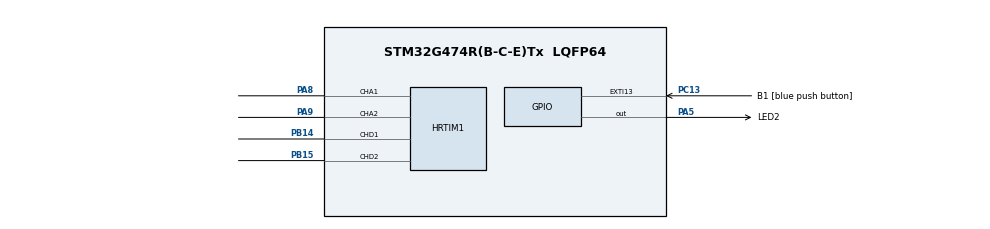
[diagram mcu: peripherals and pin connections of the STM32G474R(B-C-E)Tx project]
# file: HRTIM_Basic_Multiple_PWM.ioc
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HRTIM1.ADCTrigger_Id1=__NULL
HRTIM1.ADCTrigger_Id10=__NULL
HRTIM1.ADCTrigger_Id2=__NULL
HRTIM1.ADCTrigger_Id3=__NULL
HRTIM1.ADCTrigger_Id4=__NULL
HRTIM1.ADCTrigger_Id5=__NULL
HRTIM1.ADCTrigger_Id6=__NULL
HRTIM1.ADCTrigger_Id7=__NULL
HRTIM1.ADCTrigger_Id8=__NULL
HRTIM1.ADCTrigger_Id9=__NULL
HRTIM1.AutoDelayedMode2-Output_TA1TA2=HRTIM_AUTODELAYEDMODE_REGULAR
HRTIM1.AutoDelayedMode2-Output_TD1TD2=HRTIM_AUTODELAYEDMODE_REGULAR
HRTIM1.BurstDMAconfig-Output_TA1TA2=__NULL
HRTIM1.BurstDMAconfig-Output_TD1TD2=__NULL
HRTIM1.BurstMode-Output_TA1TA2=HRTIM_TIMERBURSTMODE_MAINTAINCLOCK
HRTIM1.BurstMode-Output_TD1TD2=HRTIM_TIMERBURSTMODE_MAINTAINCLOCK
HRTIM1.BurstModeEntryDelayed1-Output_TA1TA2=HRTIM_OUTPUTBURSTMODEENTRY_REGULAR
HRTIM1.BurstModeEntryDelayed1-Output_TD1TD2=HRTIM_OUTPUTBURSTMODEENTRY_REGULAR
HRTIM1.BurstModeEntryDelayed2-Output_TA1TA2=HRTIM_OUTPUTBURSTMODEENTRY_REGULAR
HRTIM1.BurstModeEntryDelayed2-Output_TD1TD2=HRTIM_OUTPUTBURSTMODEENTRY_REGULAR
HRTIM1.CaptureUnit1-Output_TA1TA2=__NULL
HRTIM1.CaptureUnit1-Output_TD1TD2=__NULL
HRTIM1.CaptureUnit2-Output_TA1TA2=__NULL
HRTIM1.CaptureUnit2-Output_TD1TD2=__NULL
HRTIM1.ChopperModeEnable1-Output_TA1TA2=HRTIM_OUTPUTCHOPPERMODE_DISABLED
HRTIM1.ChopperModeEnable1-Output_TD1TD2=HRTIM_OUTPUTCHOPPERMODE_DISABLED
HRTIM1.ChopperModeEnable2-Output_TA1TA2=HRTIM_OUTPUTCHOPPERMODE_DISABLED
HRTIM1.ChopperModeEnable2-Output_TD1TD2=HRTIM_OUTPUTCHOPPERMODE_DISABLED
HRTIM1.ChopperModeconfig-Output_TA1TA2=__NULL
HRTIM1.ChopperModeconfig-Output_TD1TD2=__NULL
HRTIM1.CompareUnit1-Output_TA1TA2=HRTIM_COMPAREUNIT_1
HRTIM1.CompareUnit1-Output_TD1TD2=HRTIM_COMPAREUNIT_1
HRTIM1.CompareUnit2-Output_TA1TA2=HRTIM_COMPAREUNIT_2
HRTIM1.CompareUnit2-Output_TD1TD2=HRTIM_COMPAREUNIT_2
HRTIM1.CompareUnit3-Output_TA1TA2=HRTIM_COMPAREUNIT_3
HRTIM1.CompareUnit3-Output_TD1TD2=__NULL
HRTIM1.CompareUnit4-Output_TA1TA2=__NULL
HRTIM1.CompareUnit4-Output_TD1TD2=__NULL
HRTIM1.CompareValue1-Output_TA1TA2=TIMA_PERIOD/4
HRTIM1.CompareValue1-Output_TD1TD2=TIMD_PERIOD/4
HRTIM1.CompareValue2-Output_TA1TA2=TIMA_PERIOD/2
HRTIM1.CompareValue2-Output_TD1TD2=(3*TIMD_PERIOD)/4
HRTIM1.CompareValue3-Output_TA1TA2=(3*TIMA_PERIOD)/4
HRTIM1.Configuration_TA=Waveform
HRTIM1.Configuration_TD=Waveform
HRTIM1.DACSynchro-Output_TA1TA2=HRTIM_DACSYNC_NONE
HRTIM1.DACSynchro-Output_TD1TD2=HRTIM_DACSYNC_NONE
HRTIM1.DeadTimeInsertion-Output_TA1TA2=HRTIM_TIMDEADTIMEINSERTION_DISABLED
HRTIM1.DeadTimeInsertion-Output_TD1TD2=HRTIM_TIMDEADTIMEINSERTION_DISABLED
HRTIM1.Deadtimeconfig-Output_TA1TA2=__NULL
HRTIM1.Deadtimeconfig-Output_TD1TD2=__NULL
HRTIM1.DelayedProtectionMode-Output_TA1TA2=HRTIM_TIMER_A_B_C_DELAYEDPROTECTION_DISABLED
HRTIM1.DelayedProtectionMode-Output_TD1TD2=HRTIM_TIMER_D_E_DELAYEDPROTECTION_DISABLED
HRTIM1.DualChannelDacEnableFake_TA-Output_TA1TA2=HRTIM_TIMER_DCDE_DISABLED
HRTIM1.DualChannelDacEnableFake_TD-Output_TD1TD2=HRTIM_TIMER_DCDE_DISABLED
HRTIM1.Enable=HRTIM_BURSTMODECTL_DISABLED
HRTIM1.Event1-Output_TA1TA2=__NULL
HRTIM1.Event1-Output_TD1TD2=__NULL
HRTIM1.Event10-Output_TA1TA2=__NULL
HRTIM1.Event10-Output_TD1TD2=__NULL
HRTIM1.Event2-Output_TA1TA2=__NULL
HRTIM1.Event2-Output_TD1TD2=__NULL
HRTIM1.Event3-Output_TA1TA2=__NULL
HRTIM1.Event3-Output_TD1TD2=__NULL
HRTIM1.Event4-Output_TA1TA2=__NULL
HRTIM1.Event4-Output_TD1TD2=__NULL
HRTIM1.Event5-Output_TA1TA2=__NULL
HRTIM1.Event5-Output_TD1TD2=__NULL
HRTIM1.Event6-Output_TA1TA2=__NULL
HRTIM1.Event6-Output_TD1TD2=__NULL
HRTIM1.Event7-Output_TA1TA2=__NULL
HRTIM1.Event7-Output_TD1TD2=__NULL
HRTIM1.Event8-Output_TA1TA2=__NULL
HRTIM1.Event8-Output_TD1TD2=__NULL
HRTIM1.Event9-Output_TA1TA2=__NULL
HRTIM1.Event9-Output_TD1TD2=__NULL
HRTIM1.EventEnableA-Output_TA1TA2=__NULL
HRTIM1.EventEnableA-Output_TD1TD2=__NULL
HRTIM1.Event_EEV1=__NULL
HRTIM1.Event_EEV10=__NULL
HRTIM1.Event_EEV2=__NULL
HRTIM1.Event_EEV3=__NULL
HRTIM1.Event_EEV4=__NULL
HRTIM1.Event_EEV5=__NULL
HRTIM1.Event_EEV6=__NULL
HRTIM1.Event_EEV7=__NULL
HRTIM1.Event_EEV8=__NULL
HRTIM1.Event_EEV9=__NULL
HRTIM1.FaultLevel1-Output_TA1TA2=HRTIM_OUTPUTFAULTLEVEL_NONE
HRTIM1.FaultLevel1-Output_TD1TD2=HRTIM_OUTPUTFAULTLEVEL_NONE
HRTIM1.FaultLevel2-Output_TA1TA2=HRTIM_OUTPUTFAULTLEVEL_NONE
HRTIM1.FaultLevel2-Output_TD1TD2=HRTIM_OUTPUTFAULTLEVEL_NONE
HRTIM1.FaultLock-Output_TA1TA2=HRTIM_TIMFAULTLOCK_READWRITE
HRTIM1.FaultLock-Output_TD1TD2=HRTIM_TIMFAULTLOCK_READWRITE
HRTIM1.Fault_Line1=__NULL
HRTIM1.Fault_Line2=__NULL
HRTIM1.Fault_Line3=__NULL
HRTIM1.Fault_Line4=__NULL
HRTIM1.Fault_Line5=__NULL
HRTIM1.Fault_Line6=__NULL
HRTIM1.GreaterCMP1_TA=HRTIM_TIMERGTCMP1_GREATER
HRTIM1.GreaterCMP1_TD=HRTIM_TIMERGTCMP1_EQUAL
HRTIM1.GreaterCMP3_TA=HRTIM_TIMERGTCMP3_EQUAL
HRTIM1.HRTIMInterruptResquests1=HRTIM_IT_NONE
HRTIM1.HRTIMInterruptResquests2=HRTIM_IT_NONE
HRTIM1.HRTIMInterruptResquests3=HRTIM_IT_NONE
HRTIM1.HRTIMInterruptResquests4=HRTIM_IT_NONE
HRTIM1.HRTIMInterruptResquests5=HRTIM_IT_NONE
HRTIM1.HRTIMInterruptResquests6=HRTIM_IT_NONE
HRTIM1.HRTIMInterruptResquests7=HRTIM_IT_NONE
HRTIM1.HRTIMInterruptResquests8=HRTIM_IT_NONE
HRTIM1.HRTIMInterruptResquests9=HRTIM_IT_NONE
HRTIM1.IdleLevel1-Output_TA1TA2=HRTIM_OUTPUTIDLELEVEL_INACTIVE
HRTIM1.IdleLevel1-Output_TD1TD2=HRTIM_OUTPUTIDLELEVEL_INACTIVE
HRTIM1.IdleLevel2-Output_TA1TA2=HRTIM_OUTPUTIDLELEVEL_INACTIVE
HRTIM1.IdleLevel2-Output_TD1TD2=HRTIM_OUTPUTIDLELEVEL_INACTIVE
HRTIM1.IdleMode1-Output_TA1TA2=HRTIM_OUTPUTIDLEMODE_NONE
HRTIM1.IdleMode1-Output_TD1TD2=HRTIM_OUTPUTIDLEMODE_NONE
HRTIM1.IdleMode2-Output_TA1TA2=HRTIM_OUTPUTIDLEMODE_NONE
HRTIM1.IdleMode2-Output_TD1TD2=HRTIM_OUTPUTIDLEMODE_NONE
HRTIM1.InterleavedMode-Output_TA1TA2=HRTIM_INTERLEAVED_MODE_DISABLED
HRTIM1.InterleavedMode-Output_TD1TD2=HRTIM_INTERLEAVED_MODE_DISABLED
HRTIM1.ModeTimeBase-Output_TA1TA2=HRTIM_MODE_CONTINUOUS
HRTIM1.ModeTimeBase-Output_TD1TD2=HRTIM_MODE_CONTINUOUS
HRTIM1.NumberDMARequests_TA=0
HRTIM1.NumberDMARequests_TD=0
HRTIM1.NumberFaultEnable-Output_TA1TA2=0
HRTIM1.NumberFaultEnable-Output_TD1TD2=0
HRTIM1.NumberInterruptRequests-Output_TA1TA2=0
HRTIM1.NumberInterruptRequests-Output_TD1TD2=0
HRTIM1.NumberResetSource1-Output_TA1TA2=1
HRTIM1.NumberResetSource1-Output_TD1TD2=1
HRTIM1.NumberResetSource2_TA=1
HRTIM1.NumberResetSource2_TD=1
HRTIM1.NumberResetTrigger-Output_TA1TA2=0
HRTIM1.NumberResetTrigger-Output_TD1TD2=0
HRTIM1.NumberSetSource1-Output_TA1TA2=1
HRTIM1.NumberSetSource1-Output_TD1TD2=1
HRTIM1.NumberSetSource2_TA=1
HRTIM1.NumberSetSource2_TD=1
HRTIM1.NumberUpdateTrigger-Output_TA1TA2=0
HRTIM1.NumberUpdateTrigger-Output_TD1TD2=0
HRTIM1.Output1-Output_TA1TA2=HRTIM_OUTPUT_TA1
HRTIM1.Output1-Output_TD1TD2=HRTIM_OUTPUT_TD1
HRTIM1.Output2-Output_TA1TA2=HRTIM_OUTPUT_TA2
HRTIM1.Output2-Output_TD1TD2=HRTIM_OUTPUT_TD2
HRTIM1.Periode_TA=TIMA_PERIOD
HRTIM1.Periode_TD=TIMD_PERIOD
HRTIM1.Polarity1-Output_TA1TA2=HRTIM_OUTPUTPOLARITY_HIGH
HRTIM1.Polarity1-Output_TD1TD2=HRTIM_OUTPUTPOLARITY_HIGH
HRTIM1.Polarity2-Output_TA1TA2=HRTIM_OUTPUTPOLARITY_HIGH
HRTIM1.Polarity2-Output_TD1TD2=HRTIM_OUTPUTPOLARITY_HIGH
HRTIM1.PreloadEnable-Output_TA1TA2=HRTIM_PRELOAD_DISABLED
HRTIM1.PreloadEnable-Output_TD1TD2=HRTIM_PRELOAD_DISABLED
HRTIM1.PushPull-Output_TA1TA2=HRTIM_TIMPUSHPULLMODE_DISABLED
HRTIM1.PushPull-Output_TD1TD2=HRTIM_TIMPUSHPULLMODE_DISABLED
HRTIM1.ReSyncUpdate-Output_TA1TA2=HRTIM_TIMERESYNC_UPDATE_UNCONDITIONAL
HRTIM1.ReSyncUpdate-Output_TD1TD2=HRTIM_TIMERESYNC_UPDATE_UNCONDITIONAL
HRTIM1.RepetitionUpdate-Output_TA1TA2=HRTIM_UPDATEONREPETITION_DISABLED
HRTIM1.RepetitionUpdate-Output_TD1TD2=HRTIM_UPDATEONREPETITION_DISABLED
HRTIM1.ResetOnSync-Output_TA1TA2=HRTIM_SYNCRESET_DISABLED
HRTIM1.ResetOnSync-Output_TD1TD2=HRTIM_SYNCRESET_DISABLED
HRTIM1.ResetOutput1_Source1-Output_TA1TA2=HRTIM_OUTPUTRESET_TIMCMP1
HRTIM1.ResetOutput1_Source1-Output_TD1TD2=HRTIM_OUTPUTRESET_TIMCMP1
HRTIM1.ResetOutput2_Source1-Output_TA1TA2=HRTIM_OUTPUTRESET_TIMCMP3
HRTIM1.ResetOutput2_Source1-Output_TD1TD2=HRTIM_OUTPUTRESET_TIMPER
HRTIM1.ResetUpdate-Output_TA1TA2=HRTIM_TIMUPDATEONRESET_DISABLED
HRTIM1.ResetUpdate-Output_TD1TD2=HRTIM_TIMUPDATEONRESET_DISABLED
HRTIM1.SetOutput1_Source1-Output_TA1TA2=HRTIM_OUTPUTSET_TIMPER
HRTIM1.SetOutput1_Source1-Output_TD1TD2=HRTIM_OUTPUTSET_TIMPER
HRTIM1.SetOutput2_Source1-Output_TA1TA2=HRTIM_OUTPUTSET_TIMCMP2
HRTIM1.SetOutput2_Source1-Output_TD1TD2=HRTIM_OUTPUTSET_TIMCMP2
HRTIM1.StartOnSync-Output_TA1TA2=HRTIM_SYNCSTART_DISABLED
HRTIM1.StartOnSync-Output_TD1TD2=HRTIM_SYNCSTART_DISABLED
HRTIM1.SwapA=__NULL
HRTIM1.SwapD=__NULL
HRTIM1.SyncOptions=HRTIM_SYNCOPTION_NONE
HRTIM1.TimerIdx-Output_TA1TA2=HRTIM_TIMERINDEX_TIMER_A
HRTIM1.TimerIdx-Output_TD1TD2=HRTIM_TIMERINDEX_TIMER_D
HRTIM1.TrigHalf_TA=HRTIM_TIMERTRIGHALF_DISABLED
HRTIM1.TrigHalf_TD=HRTIM_TIMERTRIGHALF_DISABLED
HRTIM1.UpDownMode-Output_TA1TA2=HRTIM_TIMERUPDOWNMODE_UP
HRTIM1.UpDownMode-Output_TD1TD2=HRTIM_TIMERUPDOWNMODE_UP
HRTIM1.UpdateGating-Output_TA1TA2=HRTIM_UPDATEGATING_INDEPENDENT
HRTIM1.UpdateGating-Output_TD1TD2=HRTIM_UPDATEGATING_INDEPENDENT
Mcu.Family=STM32G4
Mcu.Name=STM32G474R(B-C-E)Tx
Mcu.Package=LQFP64
Mcu.UserConstants=HRTIM_INPUT_CLOCK,170000000;TIMA_PWM_FREQ,100000
NVIC.EXTI15_10_IRQn=true\:0\:0\:false\:false\:true\:true\:true\:true
NVIC.PriorityGroup=NVIC_PRIORITYGROUP_4
PA13.GPIO_Label=T_SWDIO
PA13.Mode=Serial_Wire
PA13.Signal=SYS_JTMS-SWDIO
PA14.GPIO_Label=T_SWCLK
PA14.Mode=Serial_Wire
PA14.Signal=SYS_JTCK-SWCLK
PA5.GPIO_Label=LED2
PA5.Signal=GPIO_Output
PA8.Mode=Output_TA1TA2
PA8.Signal=HRTIM1_CHA1
PA9.Mode=Output_TA1TA2
PA9.Signal=HRTIM1_CHA2
PB14.Mode=Output_TD1TD2
PB14.Signal=HRTIM1_CHD1
PB15.Mode=Output_TD1TD2
PB15.Signal=HRTIM1_CHD2
PB3.GPIO_Label=T_SWO
PB3.Signal=SYS_JTDO-SWO
PC13.GPIO_Label=B1 [blue push button]
PC13.Signal=GPXTI13
PC14-OSC32_IN.Signal=RCC_OSC32_IN
PC15-OSC32_OUT.Signal=RCC_OSC32_OUT
PC4.GPIO_Label=USART1_TX [STLINKV3E_VCP_RX]
PC4.Signal=USART1_TX
PC5.GPIO_Label=USART1_RX [STLINKV3E_VCP_TX]
PC5.Signal=USART1_RX
PF0-OSC_IN.Mode=HSE-External-Oscillator
PF0-OSC_IN.Signal=RCC_OSC_IN
PF1-OSC_OUT.Mode=HSE-External-Oscillator
PF1-OSC_OUT.Signal=RCC_OSC_OUT
ProjectManager.HeapSize=0x200
ProjectManager.StackSize=0x400
ProjectManager.TargetToolchain=EWARM V8.32
RCC.ADC12Freq_Value=170000000
RCC.ADC345Freq_Value=170000000
RCC.AHBFreq_Value=170000000
RCC.APB1Freq_Value=170000000
RCC.APB1TimFreq_Value=170000000
RCC.APB2Freq_Value=170000000
RCC.APB2TimFreq_Value=170000000
RCC.CortexFreq_Value=170000000
RCC.EXTERNAL_CLOCK_VALUE=12288000
RCC.HCLKFreq_Value=170000000
RCC.HSE_VALUE=24000000
RCC.HSI48_VALUE=48000000
RCC.HSI_VALUE=16000000
RCC.LSE_VALUE=32768
RCC.PLLM=RCC_PLLM_DIV6
RCC.PLLN=85
RCC.PLLSourceVirtual=RCC_PLLSOURCE_HSE
RCC.SYSCLKFreq_VALUE=170000000
RCC.SYSCLKSource=RCC_SYSCLKSOURCE_PLLCLK
RCC.USBFreq_Value=170000000
RCC.VCOOutputFreq_Value=340000000
VP_SYS_VS_DBSignals.Mode=DisableDeadBatterySignals
board=custom

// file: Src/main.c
/* USER CODE BEGIN Header */
/**
  ******************************************************************************
  * @file    Examples_LL/HRTIM/HRTIM_Basic_Multiple_PWM/Src/main.c
  * @author  MCD Application Team
  * @brief   This example describes how to configure and use HRTIM through
  *          the STM32G4xx LL API.
  ******************************************************************************
  * @attention
  *
  * Copyright (c) 2019 STMicroelectronics.
  * All rights reserved.
  *
  * This software is licensed under terms that can be found in the LICENSE file
  * in the root directory of this software component.
  * If no LICENSE file comes with this software, it is provided AS-IS.
  *
  ******************************************************************************
  */
/* USER CODE END Header */
#include "main.h"

/* USER CODE BEGIN PD */

#define TIMD_PWM_FREQ (uint32_t)(TIMA_PWM_FREQ/3)

/* Formula below works for PWM frequency > 83kHz (with prescaler ratio = 1) */
#define TIMA_PERIOD ((uint16_t)(((uint64_t)HRTIM_INPUT_CLOCK * 32) / TIMA_PWM_FREQ))

/* Formula below works for PWM frequency > 20.8kHz (with prescaler ratio = 4) */
#define TIMD_PERIOD ((uint16_t)(((uint64_t)HRTIM_INPUT_CLOCK * 8) / TIMD_PWM_FREQ))

/* USER CODE END PD */

void SystemClock_Config(void);
static void MX_GPIO_Init(void);
static void MX_HRTIM1_Init(void);

int main(void)
{

  /* MCU Configuration--------------------------------------------------------*/

  /* Reset of all peripherals, Initializes the Flash interface and the Systick. */
  LL_APB2_GRP1_EnableClock(LL_APB2_GRP1_PERIPH_SYSCFG);
  LL_APB1_GRP1_EnableClock(LL_APB1_GRP1_PERIPH_PWR);

  /* System interrupt init*/
  NVIC_SetPriorityGrouping(NVIC_PRIORITYGROUP_4);

  /** Disable the internal Pull-Up in Dead Battery pins of UCPD peripheral
  */
  LL_PWR_DisableUCPDDeadBattery();

  /* Configure the system clock */
  SystemClock_Config();

  /* Initialize all configured peripherals */
  MX_GPIO_Init();
  MX_HRTIM1_Init();
  /* USER CODE BEGIN 2 */

  /* Enable HRTIM's outputs TA1, TA2, TD1 and TD2, and start Timer A and D */
  LL_HRTIM_EnableOutput(HRTIM1, LL_HRTIM_OUTPUT_TA1
                        | LL_HRTIM_OUTPUT_TA2
                        | LL_HRTIM_OUTPUT_TD1
                        | LL_HRTIM_OUTPUT_TD2);
  LL_HRTIM_TIM_CounterEnable(HRTIM1, LL_HRTIM_TIMER_A | LL_HRTIM_TIMER_D);

  /* USER CODE END 2 */

  /* Infinite loop */
  while (1)
  {

    /* USER CODE BEGIN 3 */
    LL_GPIO_TogglePin(LED2_GPIO_Port, LED2_Pin);

    /* Insert delay 100 ms */
    LL_mDelay(100);

  }
  /* USER CODE END 3 */
}

void SystemClock_Config(void)
{
  LL_FLASH_SetLatency(LL_FLASH_LATENCY_4);
  while(LL_FLASH_GetLatency() != LL_FLASH_LATENCY_4)
  {
  }
  LL_PWR_EnableRange1BoostMode();
  LL_RCC_HSE_Enable();
   /* Wait till HSE is ready */
  while(LL_RCC_HSE_IsReady() != 1)
  {
  }

  LL_RCC_PLL_ConfigDomain_SYS(LL_RCC_PLLSOURCE_HSE, LL_RCC_PLLM_DIV_6, 85, LL_RCC_PLLR_DIV_2);
  LL_RCC_PLL_EnableDomain_SYS();
  LL_RCC_PLL_Enable();
   /* Wait till PLL is ready */
  while(LL_RCC_PLL_IsReady() != 1)
  {
  }

  LL_RCC_SetSysClkSource(LL_RCC_SYS_CLKSOURCE_PLL);
  LL_RCC_SetAHBPrescaler(LL_RCC_SYSCLK_DIV_2);
   /* Wait till System clock is ready */
  while(LL_RCC_GetSysClkSource() != LL_RCC_SYS_CLKSOURCE_STATUS_PLL)
  {
  }

  /* Insure 1us transition state at intermediate medium speed clock*/
  for (__IO uint32_t i = (170 >> 1); i !=0; i--);

  /* Set AHB prescaler*/
  LL_RCC_SetAHBPrescaler(LL_RCC_SYSCLK_DIV_1);
  LL_RCC_SetAPB1Prescaler(LL_RCC_APB1_DIV_1);
  LL_RCC_SetAPB2Prescaler(LL_RCC_APB2_DIV_1);

  LL_Init1msTick(170000000);

  LL_SetSystemCoreClock(170000000);
}

static void MX_HRTIM1_Init(void)
{

  LL_GPIO_InitTypeDef GPIO_InitStruct = {0};

  /* Peripheral clock enable */
  LL_APB2_GRP1_EnableClock(LL_APB2_GRP1_PERIPH_HRTIM1);

  LL_HRTIM_ConfigDLLCalibration(HRTIM1, LL_HRTIM_DLLCALIBRATION_MODE_CONTINUOUS, LL_HRTIM_DLLCALIBRATION_RATE_3);

  /* Poll for DLL end of calibration */
#if (USE_TIMEOUT == 1)
  uint32_t Timeout = 10; /* Timeout Initialization */
#endif  /*USE_TIMEOUT*/

  while(LL_HRTIM_IsActiveFlag_DLLRDY(HRTIM1) == RESET){
#if (USE_TIMEOUT == 1)
    if (LL_SYSTICK_IsActiveCounterFlag())  /* Check Systick counter flag to decrement the time-out value */
    {
        if(Timeout-- == 0)
        {
          Error_Handler();  /* error management */
        }
    }
#endif  /* USE_TIMEOUT */
  }

  LL_HRTIM_TIM_SetPrescaler(HRTIM1, LL_HRTIM_TIMER_A, LL_HRTIM_PRESCALERRATIO_MUL32);
  LL_HRTIM_TIM_SetCounterMode(HRTIM1, LL_HRTIM_TIMER_A, LL_HRTIM_MODE_CONTINUOUS);
  LL_HRTIM_TIM_SetPeriod(HRTIM1, LL_HRTIM_TIMER_A, TIMA_PERIOD);
  LL_HRTIM_TIM_SetRepetition(HRTIM1, LL_HRTIM_TIMER_A, 0x00);
  LL_HRTIM_TIM_SetUpdateGating(HRTIM1, LL_HRTIM_TIMER_A, LL_HRTIM_UPDATEGATING_INDEPENDENT);
  LL_HRTIM_TIM_SetCountingMode(HRTIM1, LL_HRTIM_TIMER_A, LL_HRTIM_COUNTING_MODE_UP);
  LL_HRTIM_TIM_SetTriggeredHalfMode(HRTIM1, LL_HRTIM_TIMER_A, LL_HRTIM_TRIGHALF_DISABLED);
  LL_HRTIM_TIM_SetComp1Mode(HRTIM1, LL_HRTIM_TIMER_A, LL_HRTIM_GTCMP1_GREATER);
  LL_HRTIM_TIM_SetComp3Mode(HRTIM1, LL_HRTIM_TIMER_A, LL_HRTIM_GTCMP3_EQUAL);
  LL_HRTIM_TIM_SetDACTrig(HRTIM1, LL_HRTIM_TIMER_A, LL_HRTIM_DACTRIG_NONE);
  LL_HRTIM_TIM_DisableHalfMode(HRTIM1, LL_HRTIM_TIMER_A);
  LL_HRTIM_TIM_SetInterleavedMode(HRTIM1, LL_HRTIM_TIMER_A, LL_HRTIM_INTERLEAVED_MODE_DISABLED);
  LL_HRTIM_TIM_DisableStartOnSync(HRTIM1, LL_HRTIM_TIMER_A);
  LL_HRTIM_TIM_DisableResetOnSync(HRTIM1, LL_HRTIM_TIMER_A);
  LL_HRTIM_TIM_DisablePreload(HRTIM1, LL_HRTIM_TIMER_A);
  LL_HRTIM_TIM_SetUpdateTrig(HRTIM1, LL_HRTIM_TIMER_A, LL_HRTIM_UPDATETRIG_NONE|LL_HRTIM_UPDATETRIG_NONE);
  LL_HRTIM_TIM_SetResetTrig(HRTIM1, LL_HRTIM_TIMER_A, LL_HRTIM_RESETTRIG_NONE);
  LL_HRTIM_TIM_DisablePushPullMode(HRTIM1, LL_HRTIM_TIMER_A);
  LL_HRTIM_TIM_DisableDeadTime(HRTIM1, LL_HRTIM_TIMER_A);
  LL_HRTIM_TIM_SetBurstModeOption(HRTIM1, LL_HRTIM_TIMER_A, LL_HRTIM_BURSTMODE_MAINTAINCLOCK);
  LL_HRTIM_ForceUpdate(HRTIM1, LL_HRTIM_TIMER_A);
  LL_HRTIM_TIM_DisableResyncUpdate(HRTIM1, LL_HRTIM_TIMER_A);
  LL_HRTIM_TIM_SetCompare1(HRTIM1, LL_HRTIM_TIMER_A, TIMA_PERIOD/4);
  LL_HRTIM_TIM_SetCompareMode(HRTIM1, LL_HRTIM_TIMER_A, LL_HRTIM_COMPAREUNIT_2, LL_HRTIM_COMPAREMODE_REGULAR);
  LL_HRTIM_TIM_SetCompare2(HRTIM1, LL_HRTIM_TIMER_A, TIMA_PERIOD/2);
  LL_HRTIM_TIM_SetCompare3(HRTIM1, LL_HRTIM_TIMER_A, (3*TIMA_PERIOD)/4);
  LL_HRTIM_OUT_SetPolarity(HRTIM1, LL_HRTIM_OUTPUT_TA1, LL_HRTIM_OUT_POSITIVE_POLARITY);
  LL_HRTIM_OUT_SetOutputSetSrc(HRTIM1, LL_HRTIM_OUTPUT_TA1, LL_HRTIM_OUTPUTSET_TIMPER);
  LL_HRTIM_OUT_SetOutputResetSrc(HRTIM1, LL_HRTIM_OUTPUT_TA1, LL_HRTIM_OUTPUTRESET_TIMCMP1);
  LL_HRTIM_OUT_SetIdleMode(HRTIM1, LL_HRTIM_OUTPUT_TA1, LL_HRTIM_OUT_NO_IDLE);
  LL_HRTIM_OUT_SetIdleLevel(HRTIM1, LL_HRTIM_OUTPUT_TA1, LL_HRTIM_OUT_IDLELEVEL_INACTIVE);
  LL_HRTIM_OUT_SetFaultState(HRTIM1, LL_HRTIM_OUTPUT_TA1, LL_HRTIM_OUT_FAULTSTATE_NO_ACTION);
  LL_HRTIM_OUT_SetChopperMode(HRTIM1, LL_HRTIM_OUTPUT_TA1, LL_HRTIM_OUT_CHOPPERMODE_DISABLED);
  LL_HRTIM_OUT_SetPolarity(HRTIM1, LL_HRTIM_OUTPUT_TA2, LL_HRTIM_OUT_POSITIVE_POLARITY);
  LL_HRTIM_OUT_SetOutputSetSrc(HRTIM1, LL_HRTIM_OUTPUT_TA2, LL_HRTIM_OUTPUTSET_TIMCMP2);
  LL_HRTIM_OUT_SetOutputResetSrc(HRTIM1, LL_HRTIM_OUTPUT_TA2, LL_HRTIM_OUTPUTRESET_TIMCMP3);
  LL_HRTIM_OUT_SetIdleMode(HRTIM1, LL_HRTIM_OUTPUT_TA2, LL_HRTIM_OUT_NO_IDLE);
  LL_HRTIM_OUT_SetIdleLevel(HRTIM1, LL_HRTIM_OUTPUT_TA2, LL_HRTIM_OUT_IDLELEVEL_INACTIVE);
  LL_HRTIM_OUT_SetFaultState(HRTIM1, LL_HRTIM_OUTPUT_TA2, LL_HRTIM_OUT_FAULTSTATE_NO_ACTION);
  LL_HRTIM_OUT_SetChopperMode(HRTIM1, LL_HRTIM_OUTPUT_TA2, LL_HRTIM_OUT_CHOPPERMODE_DISABLED);

  /* Poll for DLL end of calibration */
#if (USE_TIMEOUT == 1)
  uint32_t Timeout = 10; /* Timeout Initialization */
#endif  /*USE_TIMEOUT*/

  while(LL_HRTIM_IsActiveFlag_DLLRDY(HRTIM1) == RESET){
#if (USE_TIMEOUT == 1)
    if (LL_SYSTICK_IsActiveCounterFlag())  /* Check Systick counter flag to decrement the time-out value */
    {
        if(Timeout-- == 0)
        {
          Error_Handler();  /* error management */
        }
    }
#endif  /* USE_TIMEOUT */
  }

  LL_HRTIM_TIM_SetPrescaler(HRTIM1, LL_HRTIM_TIMER_D, LL_HRTIM_PRESCALERRATIO_MUL32);
  LL_HRTIM_TIM_SetCounterMode(HRTIM1, LL_HRTIM_TIMER_D, LL_HRTIM_MODE_CONTINUOUS);
  LL_HRTIM_TIM_SetPeriod(HRTIM1, LL_HRTIM_TIMER_D, TIMD_PERIOD);
  LL_HRTIM_TIM_SetRepetition(HRTIM1, LL_HRTIM_TIMER_D, 0x00);
  LL_HRTIM_TIM_SetUpdateGating(HRTIM1, LL_HRTIM_TIMER_D, LL_HRTIM_UPDATEGATING_INDEPENDENT);
  LL_HRTIM_TIM_SetCountingMode(HRTIM1, LL_HRTIM_TIMER_D, LL_HRTIM_COUNTING_MODE_UP);
  LL_HRTIM_TIM_SetTriggeredHalfMode(HRTIM1, LL_HRTIM_TIMER_D, LL_HRTIM_TRIGHALF_DISABLED);
  LL_HRTIM_TIM_SetComp1Mode(HRTIM1, LL_HRTIM_TIMER_D, LL_HRTIM_GTCMP1_EQUAL);
  LL_HRTIM_TIM_SetDACTrig(HRTIM1, LL_HRTIM_TIMER_D, LL_HRTIM_DACTRIG_NONE);
  LL_HRTIM_TIM_DisableHalfMode(HRTIM1, LL_HRTIM_TIMER_D);
  LL_HRTIM_TIM_SetInterleavedMode(HRTIM1, LL_HRTIM_TIMER_D, LL_HRTIM_INTERLEAVED_MODE_DISABLED);
  LL_HRTIM_TIM_DisableStartOnSync(HRTIM1, LL_HRTIM_TIMER_D);
  LL_HRTIM_TIM_DisableResetOnSync(HRTIM1, LL_HRTIM_TIMER_D);
  LL_HRTIM_TIM_DisablePreload(HRTIM1, LL_HRTIM_TIMER_D);
  LL_HRTIM_TIM_SetUpdateTrig(HRTIM1, LL_HRTIM_TIMER_D, LL_HRTIM_UPDATETRIG_NONE|LL_HRTIM_UPDATETRIG_NONE);
  LL_HRTIM_TIM_SetResetTrig(HRTIM1, LL_HRTIM_TIMER_D, LL_HRTIM_RESETTRIG_NONE);
  LL_HRTIM_TIM_DisablePushPullMode(HRTIM1, LL_HRTIM_TIMER_D);
  LL_HRTIM_TIM_DisableDeadTime(HRTIM1, LL_HRTIM_TIMER_D);
  LL_HRTIM_TIM_SetBurstModeOption(HRTIM1, LL_HRTIM_TIMER_D, LL_HRTIM_BURSTMODE_MAINTAINCLOCK);
  LL_HRTIM_ForceUpdate(HRTIM1, LL_HRTIM_TIMER_D);
  LL_HRTIM_TIM_DisableResyncUpdate(HRTIM1, LL_HRTIM_TIMER_D);
  LL_HRTIM_TIM_SetCompare1(HRTIM1, LL_HRTIM_TIMER_D, TIMD_PERIOD/4);
  LL_HRTIM_TIM_SetCompareMode(HRTIM1, LL_HRTIM_TIMER_D, LL_HRTIM_COMPAREUNIT_2, LL_HRTIM_COMPAREMODE_REGULAR);
  LL_HRTIM_TIM_SetCompare2(HRTIM1, LL_HRTIM_TIMER_D, (3*TIMD_PERIOD)/4);
  LL_HRTIM_OUT_SetPolarity(HRTIM1, LL_HRTIM_OUTPUT_TD1, LL_HRTIM_OUT_POSITIVE_POLARITY);
  LL_HRTIM_OUT_SetOutputSetSrc(HRTIM1, LL_HRTIM_OUTPUT_TD1, LL_HRTIM_OUTPUTSET_TIMPER);
  LL_HRTIM_OUT_SetOutputResetSrc(HRTIM1, LL_HRTIM_OUTPUT_TD1, LL_HRTIM_OUTPUTRESET_TIMCMP1);
  LL_HRTIM_OUT_SetIdleMode(HRTIM1, LL_HRTIM_OUTPUT_TD1, LL_HRTIM_OUT_NO_IDLE);
  LL_HRTIM_OUT_SetIdleLevel(HRTIM1, LL_HRTIM_OUTPUT_TD1, LL_HRTIM_OUT_IDLELEVEL_INACTIVE);
  LL_HRTIM_OUT_SetFaultState(HRTIM1, LL_HRTIM_OUTPUT_TD1, LL_HRTIM_OUT_FAULTSTATE_NO_ACTION);
  LL_HRTIM_OUT_SetChopperMode(HRTIM1, LL_HRTIM_OUTPUT_TD1, LL_HRTIM_OUT_CHOPPERMODE_DISABLED);
  LL_HRTIM_OUT_SetPolarity(HRTIM1, LL_HRTIM_OUTPUT_TD2, LL_HRTIM_OUT_POSITIVE_POLARITY);
  LL_HRTIM_OUT_SetOutputSetSrc(HRTIM1, LL_HRTIM_OUTPUT_TD2, LL_HRTIM_OUTPUTSET_TIMCMP2);
  LL_HRTIM_OUT_SetOutputResetSrc(HRTIM1, LL_HRTIM_OUTPUT_TD2, LL_HRTIM_OUTPUTRESET_TIMPER);
  LL_HRTIM_OUT_SetIdleMode(HRTIM1, LL_HRTIM_OUTPUT_TD2, LL_HRTIM_OUT_NO_IDLE);
  LL_HRTIM_OUT_SetIdleLevel(HRTIM1, LL_HRTIM_OUTPUT_TD2, LL_HRTIM_OUT_IDLELEVEL_INACTIVE);
  LL_HRTIM_OUT_SetFaultState(HRTIM1, LL_HRTIM_OUTPUT_TD2, LL_HRTIM_OUT_FAULTSTATE_NO_ACTION);
  LL_HRTIM_OUT_SetChopperMode(HRTIM1, LL_HRTIM_OUTPUT_TD2, LL_HRTIM_OUT_CHOPPERMODE_DISABLED);
  LL_AHB2_GRP1_EnableClock(LL_AHB2_GRP1_PERIPH_GPIOB);
  LL_AHB2_GRP1_EnableClock(LL_AHB2_GRP1_PERIPH_GPIOA);
  /**HRTIM1 GPIO Configuration
  PB14   ------> HRTIM1_CHD1
  PB15   ------> HRTIM1_CHD2
  PA8   ------> HRTIM1_CHA1
  PA9   ------> HRTIM1_CHA2
  */
  GPIO_InitStruct.Pin = LL_GPIO_PIN_14;
  GPIO_InitStruct.Mode = LL_GPIO_MODE_ALTERNATE;
  GPIO_InitStruct.Speed = LL_GPIO_SPEED_FREQ_VERY_HIGH;
  GPIO_InitStruct.OutputType = LL_GPIO_OUTPUT_PUSHPULL;
  GPIO_InitStruct.Pull = LL_GPIO_PULL_NO;
  GPIO_InitStruct.Alternate = LL_GPIO_AF_13;
  LL_GPIO_Init(GPIOB, &GPIO_InitStruct);

  GPIO_InitStruct.Pin = LL_GPIO_PIN_15;
  GPIO_InitStruct.Mode = LL_GPIO_MODE_ALTERNATE;
  GPIO_InitStruct.Speed = LL_GPIO_SPEED_FREQ_VERY_HIGH;
  GPIO_InitStruct.OutputType = LL_GPIO_OUTPUT_PUSHPULL;
  GPIO_InitStruct.Pull = LL_GPIO_PULL_NO;
  GPIO_InitStruct.Alternate = LL_GPIO_AF_13;
  LL_GPIO_Init(GPIOB, &GPIO_InitStruct);

  GPIO_InitStruct.Pin = LL_GPIO_PIN_8;
  GPIO_InitStruct.Mode = LL_GPIO_MODE_ALTERNATE;
  GPIO_InitStruct.Speed = LL_GPIO_SPEED_FREQ_VERY_HIGH;
  GPIO_InitStruct.OutputType = LL_GPIO_OUTPUT_PUSHPULL;
  GPIO_InitStruct.Pull = LL_GPIO_PULL_NO;
  GPIO_InitStruct.Alternate = LL_GPIO_AF_13;
  LL_GPIO_Init(GPIOA, &GPIO_InitStruct);

  GPIO_InitStruct.Pin = LL_GPIO_PIN_9;
  GPIO_InitStruct.Mode = LL_GPIO_MODE_ALTERNATE;
  GPIO_InitStruct.Speed = LL_GPIO_SPEED_FREQ_VERY_HIGH;
  GPIO_InitStruct.OutputType = LL_GPIO_OUTPUT_PUSHPULL;
  GPIO_InitStruct.Pull = LL_GPIO_PULL_NO;
  GPIO_InitStruct.Alternate = LL_GPIO_AF_13;
  LL_GPIO_Init(GPIOA, &GPIO_InitStruct);

}

static void MX_GPIO_Init(void)
{
  LL_EXTI_InitTypeDef EXTI_InitStruct = {0};
  LL_GPIO_InitTypeDef GPIO_InitStruct = {0};

  /* GPIO Ports Clock Enable */
  LL_AHB2_GRP1_EnableClock(LL_AHB2_GRP1_PERIPH_GPIOC);
  LL_AHB2_GRP1_EnableClock(LL_AHB2_GRP1_PERIPH_GPIOF);
  LL_AHB2_GRP1_EnableClock(LL_AHB2_GRP1_PERIPH_GPIOA);
  LL_AHB2_GRP1_EnableClock(LL_AHB2_GRP1_PERIPH_GPIOB);

  /**/
  LL_GPIO_ResetOutputPin(LED2_GPIO_Port, LED2_Pin);

  /**/
  LL_SYSCFG_SetEXTISource(LL_SYSCFG_EXTI_PORTC, LL_SYSCFG_EXTI_LINE13);

  /**/
  EXTI_InitStruct.Line_0_31 = LL_EXTI_LINE_13;
  EXTI_InitStruct.LineCommand = ENABLE;
  EXTI_InitStruct.Mode = LL_EXTI_MODE_IT;
  EXTI_InitStruct.Trigger = LL_EXTI_TRIGGER_RISING;
  LL_EXTI_Init(&EXTI_InitStruct);

  /**/
  LL_GPIO_SetPinPull(B1_GPIO_Port, B1_Pin, LL_GPIO_PULL_NO);

  /**/
  LL_GPIO_SetPinMode(B1_GPIO_Port, B1_Pin, LL_GPIO_MODE_INPUT);

  /**/
  GPIO_InitStruct.Pin = LED2_Pin;
  GPIO_InitStruct.Mode = LL_GPIO_MODE_OUTPUT;
  GPIO_InitStruct.Speed = LL_GPIO_SPEED_FREQ_LOW;
  GPIO_InitStruct.OutputType = LL_GPIO_OUTPUT_PUSHPULL;
  GPIO_InitStruct.Pull = LL_GPIO_PULL_NO;
  LL_GPIO_Init(LED2_GPIO_Port, &GPIO_InitStruct);

  /**/
  GPIO_InitStruct.Pin = USART1_TX_Pin;
  GPIO_InitStruct.Mode = LL_GPIO_MODE_ALTERNATE;
  GPIO_InitStruct.Speed = LL_GPIO_SPEED_FREQ_LOW;
  GPIO_InitStruct.OutputType = LL_GPIO_OUTPUT_PUSHPULL;
  GPIO_InitStruct.Pull = LL_GPIO_PULL_NO;
  GPIO_InitStruct.Alternate = LL_GPIO_AF_7;
  LL_GPIO_Init(USART1_TX_GPIO_Port, &GPIO_InitStruct);

  /**/
  GPIO_InitStruct.Pin = USART1_RX_Pin;
  GPIO_InitStruct.Mode = LL_GPIO_MODE_ALTERNATE;
  GPIO_InitStruct.Speed = LL_GPIO_SPEED_FREQ_LOW;
  GPIO_InitStruct.OutputType = LL_GPIO_OUTPUT_PUSHPULL;
  GPIO_InitStruct.Pull = LL_GPIO_PULL_NO;
  GPIO_InitStruct.Alternate = LL_GPIO_AF_7;
  LL_GPIO_Init(USART1_RX_GPIO_Port, &GPIO_InitStruct);

  /* EXTI interrupt init*/
  NVIC_SetPriority(EXTI15_10_IRQn, NVIC_EncodePriority(NVIC_GetPriorityGrouping(),0, 0));
  NVIC_EnableIRQ(EXTI15_10_IRQn);

}

void Error_Handler(void)
{
  /* USER CODE BEGIN Error_Handler_Debug */

  /* Turn LED2 on */
  LL_GPIO_SetOutputPin(LED2_GPIO_Port, LED2_Pin);

  /* User can add his own implementation to report the HAL error return state */
  while(1)
  {
  }
  /* USER CODE END Error_Handler_Debug */
}
